# CY8C5868AXI_LP035 register map
File version: 0.1
CY8C58LP
Registers are 8-bit, read-write, no defined reset value unless marked. A register's access mark holds for its fields unless they carry their own. Offsets are from the block's base; lines under a group give offsets from that group; [hi:lo] are bit positions; {n}, {i} and the like mark numbered series; 'fields as' and 'values as' point back to an identical list; <NAME> marks a mode.

## Memory map
0x40004394 USBUART size 0x1D0A — USBFS
0x400043A4 WaveDAC8_1_BuffAmp size 0x17A2
0x400043A8 WaveDAC8_1_VDAC8 size 0x17DA
0x400043A8 VDAC8_2 size 0x17DC
0x400043A8 IDAC8_1 size 0x17D9
0x400043A8 VDAC8_1 size 0x17DB
0x400043AA ADC_DelSig_1 size 0x17E0
0x40004614 ADC_SAR_Seq_1_SAR size 0x158D — SAR ADC
0x40004616 ADC_SAR_1 size 0x158D — SAR ADC
0x400049C8 I2C_1 size 0x19
0x4000640A SPIS_1 size 0x65
0x40006422 PWM_6 size 0x72
0x40006425 PWM_1 size 0x72
0x40006428 PWM_2 size 0x15F
0x4000642C PWM_8 size 0x150
0x4000642E PWM_5 size 0x72
0x40006469 Port_12_Status size 0x31
0x4000646B Port_4_Status size 0x31
0x4000646D Port_2_Status size 0x31
0x40006470 Port_4_Control size 0x1
0x40006476 PWM_4 size 0x122
0x40006477 Port_12_Control size 0x1
0x40006478 PWM_7 size 0x124
0x4000647A Port_2_Control size 0x1
0x40006528 PWM_3 size 0x72
0x40006544 DEBUG_UART size 0x21 — UART
0x4000656A Port_5_Status size 0x31
0x4000657A Port_5_Control size 0x1

## Port_2_Status
Base 0x4000646D
0x00 Port_2_Status_STATUS_REG
0x20 Port_2_Status_MASK_REG
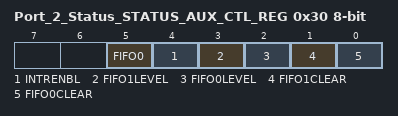
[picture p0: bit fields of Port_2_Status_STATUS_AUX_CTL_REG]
0x30 Port_2_Status_STATUS_AUX_CTL_REG
  [5] FIFO0 — FIFO0 clear
    1=ENABLED (Enable counter); 0=DISABLED (Disable counter)
  [4] INTRENBL — Enables or disables the Interrupt
    1=ENABLED (Interrupt enabled); 0=DISABLED (Interrupt disabled)
  [3] FIFO1LEVEL — FIFO level
    1=ENABLED (FIFO LVL: input mode: FIFO at least 1/2 empty; output mode: FIFO at least 1/2 full); 0=DISABLED (FIFO LVL: input mode: FIFO not full; output mode: FIFO not empty)
  [2] FIFO0LEVEL — FIFO level
    values as FIFO1LEVEL
  [1] FIFO1CLEAR — FIFO clear
    1=ENABLED (Clear FIFO state); 0=DISABLED (Normal FIFO operation)
  [0] FIFO0CLEAR — FIFO clear
    values as FIFO1CLEAR

## Port_4_Status
Base 0x4000646B
Registers as Port_2_Status (with Port_2_Status read as Port_4_Status).

## Port_12_Status
Base 0x40006469
Registers as Port_2_Status (with Port_2_Status read as Port_12_Status).

## Port_5_Status
Base 0x4000656A
Registers as Port_2_Status (with Port_2_Status read as Port_5_Status).

## Port_2_Control
Base 0x4000647A
0x00 Port_2_Control_CONTROL_REG

## Port_12_Control
Base 0x40006477
Registers as Port_2_Control (with Port_2_Control read as Port_12_Control).

## Port_5_Control
Base 0x4000657A
Registers as Port_2_Control (with Port_2_Control read as Port_5_Control).

## Port_4_Control
Base 0x40006470
Registers as Port_2_Control (with Port_2_Control read as Port_4_Control).

## DEBUG_UART — UART
Base 0x40006544
0x00 TX_DEBUG_UART_TX_DATA — TX Data Register
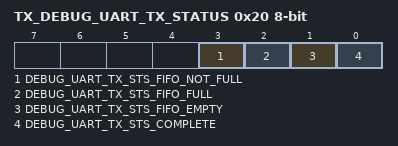
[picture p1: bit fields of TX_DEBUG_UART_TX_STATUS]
0x20 TX_DEBUG_UART_TX_STATUS — TX status register
  [3] DEBUG_UART_TX_STS_FIFO_NOT_FULL ro, [2] DEBUG_UART_TX_STS_FIFO_FULL ro, [1] DEBUG_UART_TX_STS_FIFO_EMPTY ro, [0] DEBUG_UART_TX_STS_COMPLETE ro

## USBUART — USBFS
Base 0x40004394
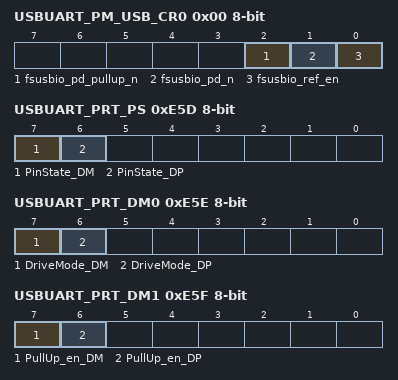
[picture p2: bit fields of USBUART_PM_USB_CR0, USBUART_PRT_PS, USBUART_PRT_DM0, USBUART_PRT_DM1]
0x00 USBUART_PM_USB_CR0 — USB Power Mode Control Register 0
  [2] fsusbio_pd_pullup_n, [1] fsusbio_pd_n, [0] fsusbio_ref_en
0x11 USBUART_PM_ACT_CFG — Active Power Mode Configuration Register
0x21 USBUART_PM_STBY_CFG — Standby Power Mode Configuration Register
0xE5D USBUART_PRT_PS — Port Pin State Register
  [7] PinState_DM ro, [6] PinState_DP ro
0xE5E USBUART_PRT_DM0 — Port Drive Mode Register
  [7] DriveMode_DM, [6] DriveMode_DP
0xE5F USBUART_PRT_DM1 — Port Drive Mode Register
  [7] PullUp_en_DM, [6] PullUp_en_DP
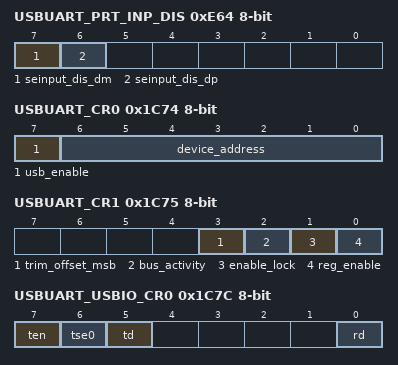
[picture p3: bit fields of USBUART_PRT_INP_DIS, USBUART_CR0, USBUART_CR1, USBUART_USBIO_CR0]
0xE64 USBUART_PRT_INP_DIS — Input buffer disable override
  [7] seinput_dis_dm, [6] seinput_dis_dp
0x1C6C USBUART_EP0_DR0 — bmRequestType
0x1C6D USBUART_EP0_DR1 — bRequest
0x1C6E USBUART_EP0_DR2 — wValueLo
0x1C6F USBUART_EP0_DR3 — wValueHi
0x1C70 USBUART_EP0_DR4 — wIndexLo
0x1C71 USBUART_EP0_DR5 — wIndexHi
0x1C72 USBUART_EP0_DR6 — lengthLo
0x1C73 USBUART_EP0_DR7 — lengthHi
0x1C74 USBUART_CR0 — USB Control Register 0
  [7] usb_enable, [6:0] device_address ro
0x1C75 USBUART_CR1 — USB Control Register 1
  [3] trim_offset_msb, [2] bus_activity, [1] enable_lock, [0] reg_enable
{0x1C6A+0x10*i} USBUART_SIE_EP{i}_CR0 (i=1..8) — The Endpoint{i} Control Register
0x1C7C USBUART_USBIO_CR0 — USBIO Control Register 0
  [7] ten, [6] tse0, [5] td, [0] rd ro
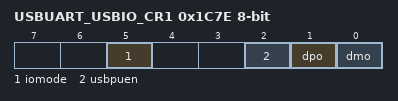
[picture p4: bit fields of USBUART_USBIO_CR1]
0x1C7E USBUART_USBIO_CR1 — USBIO Control Register 1
  [5] iomode, [2] usbpuen, [1] dpo ro, [0] dmo ro
0x1CF8 USBUART_BUF_SIZE — Dedicated Endpoint Buffer Size Register
0x1CFA USBUART_EP_ACTIVE — Endpoint Active Indication Register
0x1CFB USBUART_EP_TYPE — Endpoint Type (IN/OUT) Indication
0x1D09 USBUART_USB_CLK_EN — USB Block Clock Enable Register
